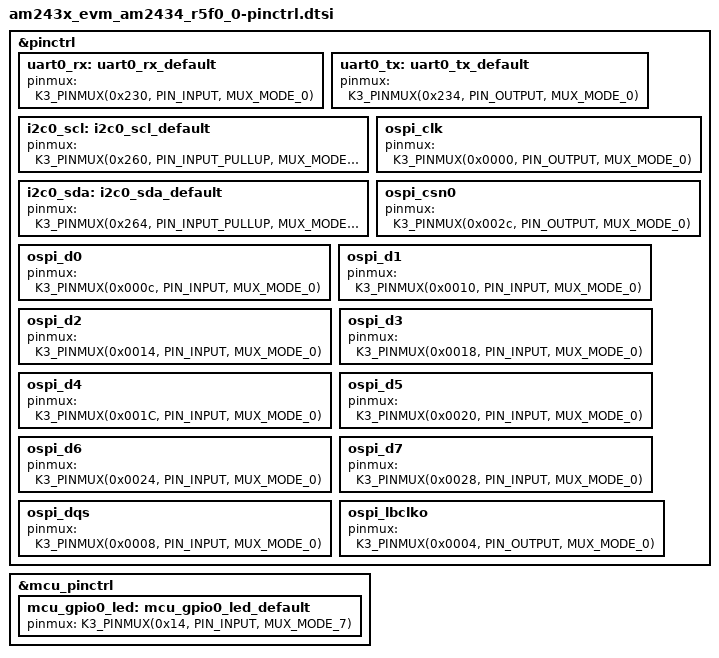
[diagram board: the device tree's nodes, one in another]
/*
 * Copyright (c) 2025 Texas Instruments Incorporated
 *
 * SPDX-License-Identifier: Apache-2.0
 */

#include <zephyr/dt-bindings/pinctrl/ti-k3-pinctrl.h>

&pinctrl {
	status = "okay";

	uart0_rx: uart0_rx_default {
		pinmux = <K3_PINMUX(0x230, PIN_INPUT, MUX_MODE_0)>;
	};

	uart0_tx: uart0_tx_default {
		pinmux = <K3_PINMUX(0x234, PIN_OUTPUT, MUX_MODE_0)>;
	};

	i2c0_scl: i2c0_scl_default {
		pinmux = <K3_PINMUX(0x260, PIN_INPUT_PULLUP, MUX_MODE_0)>;
	};

	i2c0_sda: i2c0_sda_default {
		pinmux = <K3_PINMUX(0x264, PIN_INPUT_PULLUP, MUX_MODE_0)>;
	};
  ospi_clk: ospi_clk {
		pinmux = <K3_PINMUX(0x0000, PIN_OUTPUT, MUX_MODE_0)>;
	};

	ospi_csn0: ospi_csn0 { // GPIO0 11
		pinmux = <K3_PINMUX(0x002c, PIN_OUTPUT, MUX_MODE_0)>;
	};

	ospi_d0: ospi_d0 {
		pinmux = <K3_PINMUX(0x000c, PIN_INPUT, MUX_MODE_0)>;
	};

	ospi_d1: ospi_d1 {
		pinmux = <K3_PINMUX(0x0010, PIN_INPUT, MUX_MODE_0)>;
	};

	ospi_d2: ospi_d2 {
		pinmux = <K3_PINMUX(0x0014, PIN_INPUT, MUX_MODE_0)>;
	};

	ospi_d3: ospi_d3 {
		pinmux = <K3_PINMUX(0x0018, PIN_INPUT, MUX_MODE_0)>;
	};

	ospi_d4: ospi_d4 {
		pinmux = <K3_PINMUX(0x001C, PIN_INPUT, MUX_MODE_0)>;
	};

	ospi_d5: ospi_d5 {
		pinmux = <K3_PINMUX(0x0020, PIN_INPUT, MUX_MODE_0)>;
	};

	ospi_d6: ospi_d6 {
		pinmux = <K3_PINMUX(0x0024, PIN_INPUT, MUX_MODE_0)>;
	};
  
	ospi_d7: ospi_d7 {
		pinmux = <K3_PINMUX(0x0028, PIN_INPUT, MUX_MODE_0)>;
	};

	ospi_dqs: ospi_dqs {
		pinmux = <K3_PINMUX(0x0008, PIN_INPUT, MUX_MODE_0)>;
	};

	ospi_lbclko: ospi_lbclko {
		pinmux = <K3_PINMUX(0x0004, PIN_OUTPUT, MUX_MODE_0)>;
	};
};

&mcu_pinctrl {
	status = "okay";

	mcu_gpio0_led: mcu_gpio0_led_default {
		pinmux = <K3_PINMUX(0x14, PIN_INPUT, MUX_MODE_7)>;
	};
};
